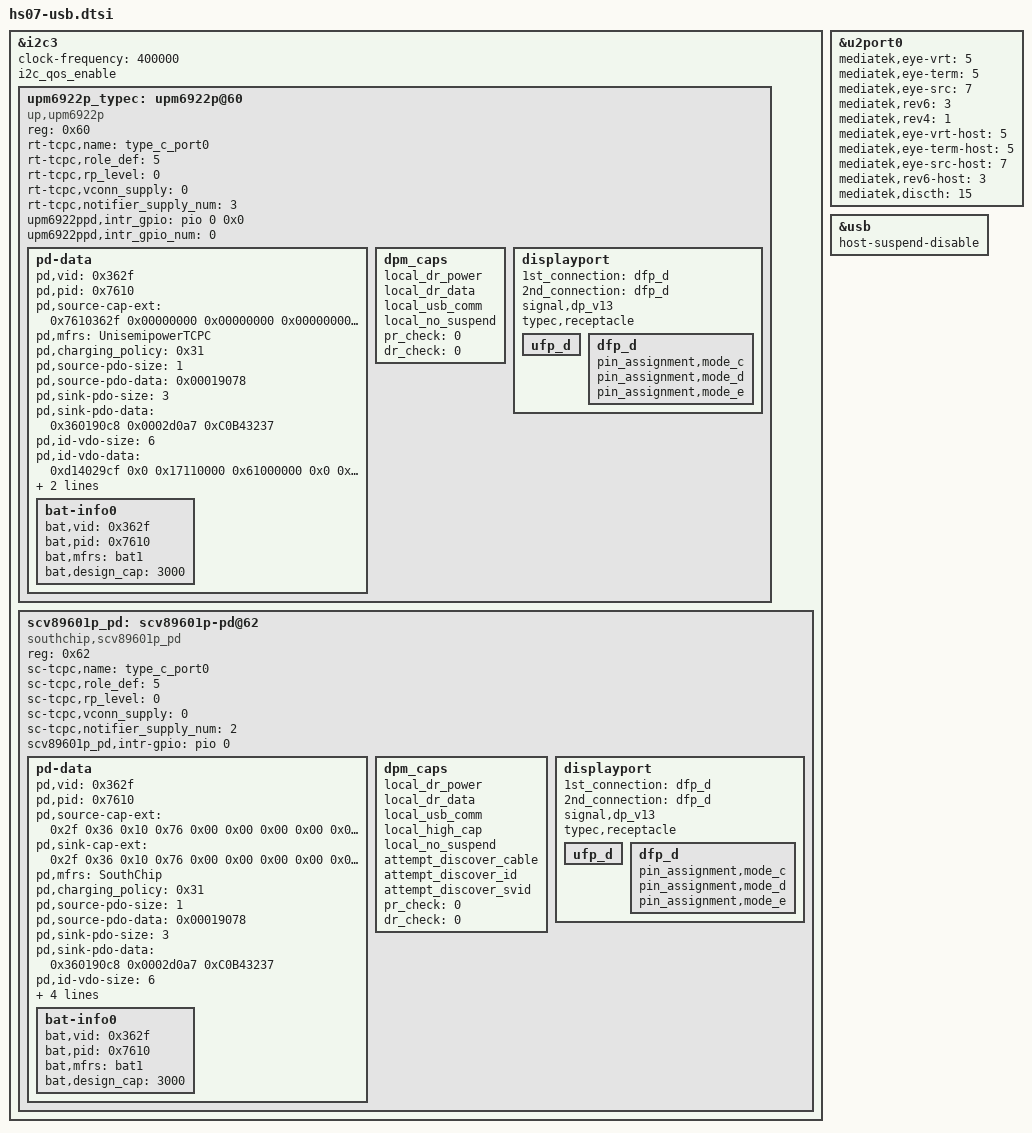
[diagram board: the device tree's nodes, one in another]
/* Note for tcpc data
* tcpc-dual,supported_modes : 0: dfp/ufp, 1: dfp, 2: ufp
* *-tcpc,role_def : 0: Unknown, 1: SNK, 2: SRC 3: DRP, 4: Try.SRC, 5: Try.SNK
* *-tcpc,rp_level: 0: Default, 1: 1.5, 2: 3.0
* *-tcpc,vconn_supply : 0: Never, 1: Always, 2: EMarkOnly, 3: StartOnly
* *-pd,charging_policy: VSAFE5V = 0, MAX_POWER = 1, CUSTOM = 2,MAX_POWER_LV = 0x21,
*                       MAX_POWER_LVIC = 0x31, MAX_POWER_HV = 0x41, MAX_POWER_HVIC = 0x51
* pd,sink-pdo-data: Fixed 5V, 500 mA <0x00019032>, Fixed 5V, 1A <0x00019064>, Fixed 5V, 2A <0x000190c8>
*                   Fixed 5V, 3A <0x0001912c>, Fixed 9V, 500 mA <0x0002d032>, Fixed 9V, 1A <0x0002d064>
*                   Fixed 9V, 2A <0x0002d0c8>, Fixed 9V, 3A <0x0002d12c>, Variable 5-9V, 1A <0x8642d064>
*                   Variable 5-9V, 2A <0x8642d0c8>, Variable 5-9V, 3A <0x8642d12c>, PPS 3V~5.9V, 3A <0xC0761E3C>
* No DP, host + device: pd,id-vdo-size = <6>;
*                       pd,id-vdo-data = <0xd14029cf 0x0 0x17110000
*                                         0x41800000 0x0 0x21800000>;
* With DP: pd,id-vdo-size = <6>;
*          pd,id-vdo-data = <0xd54029cf 0x0 0x17110000
*                            0x41800000 0x0 0x21800000>;
*/

/*HS07 code for HS07-18 by lina at 20250224 start*/
&i2c3 {
/*HS07 code for HS07-18 by lina at 20250224 end*/
	clock-frequency = <400000>;
	i2c_qos_enable;
	upm6922p_typec: upm6922p@60 {
		compatible = "up,upm6922p";
		reg = <0x60>;
		status = "okay";
		rt-tcpc,name = "type_c_port0"; /* tcpc_device's name */
		rt-tcpc,role_def = <5>; /* 0: Unknown, 1: SNK, 2: SRC */
					/* 3: DRP, 4: Try.SRC, 5: Try.SNK */
		rt-tcpc,rp_level = <0>; /* 0: Default, 1: 1.5, 2: 3.0 */
		/*HS07 code for HS07-752 by xiongxiaoliang at 20250415 start*/
		rt-tcpc,vconn_supply = <0>;  /* 0: Never, 1: Always, */
					     /* 2: EMarkOnly, 3: StartOnly */
		/*HS07 code for HS07-752 by xiongxiaoliang at 20250415 end*/
		rt-tcpc,notifier_supply_num = <3>;
		upm6922ppd,intr_gpio = <&pio 0 0x0>;
		upm6922ppd,intr_gpio_num = <0>;
		pd-data {
			pd,vid = <0x362f>;
			pd,pid = <0x7610>;
			pd,source-cap-ext = <0x7610362f 0x00000000 0x00000000
					     0x00000000 0x00000000 0x02000000>;
			pd,mfrs = "UnisemipowerTCPC";
			/*
			 *	VSAFE5V = 0, MAX_POWER = 1, CUSTOM = 2,
			 *	MAX_POWER_LV = 0x21, MAX_POWER_LVIC = 0x31
			 *	MAX_POWER_HV = 0x41, MAX_POWER_HVIC = 0x51
			 */
			 /*HS07 code for HS07-18 by lina at 20250224 start*/
			pd,charging_policy = <0x31>;
			/*HS07 code for HS07-18 by lina at 20250224 end*/
			/*
			 * Fixed 5V, 500 mA <0x00019032>
			 * Fixed 5V, 1A <0x00019064>
			 * Fixed 5V, 2A <0x000190c8>
			 * Fixed 5V, 3A <0x0001912c>
			 * Fixed 9V, 500 mA <0x0002d032>
			 * Fixed 9V, 1A <0x0002d064>
			 * Fixed 9V, 2A <0x0002d0c8>
			 * Fixed 9V, 3A <0x0002d12c>
			 * Variable 5-9V, 1A <0x8642d064>
			 * Variable 5-9V, 2A <0x8642d0c8>
			 * Variable 5-9V, 3A <0x8642d12c>
			 */
			pd,source-pdo-size = <1>;
			/*HS07 code for HS07-752 by xiongxiaoliang at 20250415 start*/
			pd,source-pdo-data = <0x00019078>;
			/*HS07 code for HS07-752 by xiongxiaoliang at 20250415 end*/
			pd,sink-pdo-size = <3>;
			/*HS07 code for HS07-2435 by xiongxiaoliang at 20250429 start*/
			pd,sink-pdo-data = <0x360190c8 0x0002d0a7 0xC0B43237>;
			/*HS07 code for HS07-2435 by xiongxiaoliang at 20250429 end*/
			/*
			 * No DP, host + device
			 *	pd,id-vdo-size = <6>;
			 *	pd,id-vdo-data = <0xd14029cf 0x0 0x17110000
						  0x61000000 0x0 0x41000000>;
			 * With DP Sink capability
			 *	pd,id-vdo-size = <6>;
			 *	pd,id-vdo-data = <0xd54029cf 0x0 0x17110000
						  0x61000000 0x0 0x41000000>;
			 */
			pd,id-vdo-size = <6>;
			pd,id-vdo-data = <0xd14029cf 0x0 0x17110000
					  0x61000000 0x0 0x41000000>;
			bat,nr = <1>;
			pd,country-nr = <0>;
			bat-info0 {
				bat,vid = <0x362f>;
				bat,pid = <0x7610>;
				bat,mfrs = "bat1";
				bat,design_cap = <3000>;
			};
		};
		/*HS07 code for HS07-18 by lina at 20250224 start*/
		dpm_caps {
		/*HS07 code for HS07-18 by lina at 20250224 end*/
			local_dr_power;
			local_dr_data;
			//local_ext_power;
			local_usb_comm;
			//local_usb_suspend;
			//local_high_cap;
			//local_give_back;
			local_no_suspend;
			/*HS07 code for HS07-752 by xiongxiaoliang at 20250415 start*/
			//local_vconn_supply;

			//attempt_discover_cable_dfp;
			//attempt_enter_dp_mode;
			//attempt_discover_cable;
			//attempt_discover_id;
			/*HS07 code for HS07-752 by xiongxiaoliang at 20250415 end*/
			/* 0: disable, 1: prefer-snk, 2: prefer-src */
			pr_check = <0>;
			//pr_reject_as_source;
			//pr_reject_as_sink;
			//pr_check_gp_source;
			//pr_check_gp_sink;

			/* 0: disable, 1: prefer_ufp, 2: prefer_dfp */
			dr_check = <0>;
			//dr_reject_as_dfp;
			//dr_reject_as_ufp;
		};
		displayport {
			/* connection type = "both", "ufp_d", "dfp_d" */
			1st_connection = "dfp_d";
			2nd_connection = "dfp_d";
			signal,dp_v13;
			//signal,dp_gen2;
			//usbr20_not_used;
			typec,receptacle;
			ufp_d {
				//pin_assignment,mode_a;
				//pin_assignment,mode_b;
				//pin_assignment,mode_c;
				//pin_assignment,mode_d;
				//pin_assignment,mode_e;
			};
			dfp_d {
				//pin_assignment,mode_a;
				//pin_assignment,mode_b;
				pin_assignment,mode_c;
				pin_assignment,mode_d;
				pin_assignment,mode_e;
				//pin_assignment,mode_f;
			};
		};
	};

	/* HS07 code for SR-AL7761A-01-164 by lina at 20250314 start */
	scv89601p_pd: scv89601p-pd@62{
		compatible = "southchip,scv89601p_pd";
		reg = <0x62>;
		status = "okay";
		sc-tcpc,name = "type_c_port0"; /* tcpc_device's name */
		sc-tcpc,role_def = <5>; /* 0: Unknown, 1: SNK, 2: SRC */
					/* 3: DRP, 4: Try.SRC, 5: Try.SNK */
		sc-tcpc,rp_level = <0>; /* 0: Default, 1: 1.5, 2: 3.0 */
		/*HS07 code for SR-AL7761A-01-20 by lina at 20250415 start*/
		sc-tcpc,vconn_supply  = <0>;  /* 0: Never, 1: Always, */
					      /* 2: EMarkOnly, 3: StartOnly */
		/*HS07 code for SR-AL7761A-01-20 by lina at 20250415 end*/
		sc-tcpc,notifier_supply_num = <2>;
		scv89601p_pd,intr-gpio = <&pio 0 IRQ_TYPE_EDGE_FALLING>;
		pd-data {
			/* HS07 code for HS07-1480 by lina at 20250425 start */
			pd,vid = <0x362f>;
			pd,pid = <0x7610>;
			pd,source-cap-ext = /bits/ 8 <0x2f 0x36 0x10 0x76
						      0x00 0x00 0x00 0x00
						      0x00 0x00 0x00 0x00
						      0x00 0x00 0x00 0x00
						      0x00 0x00 0x00 0x00
						      0x00 0x00 0x01 0x06
						      0x00>;
			pd,sink-cap-ext = /bits/ 8 <0x2f 0x36 0x10 0x76
							   0x00 0x00 0x00 0x00
							   0x01 0x00 0x00 0x00
							   0x00 0x00 0x00 0x00
							   0x01 0x00 0x00 0x00
							   0x00 0x00 0x00 0x00>;
			pd,mfrs = "SouthChip";
			/* HS07 code for HS07-1480 by lina at 20250425 end */

			/*
			 *	VSAFE5V = 0, MAX_POWER = 1, CUSTOM = 2,
			 *	MAX_POWER_LV = 0x21, MAX_POWER_LVIC = 0x31
			 *	MAX_POWER_HV = 0x41, MAX_POWER_HVIC = 0x51
			 */
			/*HS07 code for SR-AL7761A-01-20 by xiongxiaoliang at 20250319 start*/
			/*HS07 code for HS07-940 by lina at 20250418 start*/
			pd,charging_policy= <0x31>;
			/*HS07 code for HS07-940 by lina at 20250418 end*/

			/*
			 * Fixed 5V, 500 mA <0x00019032>
			 * Fixed 5V, 1A <0x00019064>
			 * Fixed 5V, 2A <0x000190c8>
			 * Fixed 5V, 3A <0x0001912c>
			 * Fixed 9V, 500 mA <0x0002d032>
			 * Fixed 9V, 1A <0x0002d064>
			 * Fixed 9V, 2A <0x0002d0c8>
			 * Fixed 9V, 3A <0x0002d12c>
			 * Variable 5-9V, 1A <0x8642d064>
			 * Variable 5-9V, 2A <0x8642d0c8>
			 * Variable 5-9V, 3A <0x8642d12c>
			 * PPS 3V~5.9V, 3A <0xC0761E3C>
			 */
			pd,source-pdo-size = <1>;
			/* Fixed 5V,0.5A */
			/*HS07 code for HS07-752 by xiongxiaoliang at 20250415 start*/
			pd,source-pdo-data = <0x00019078>;
			/*HS07 code for HS07-752 by xiongxiaoliang at 20250415 end*/
			/*HS07 code for SR-AL7761A-01-20 by lina at 20250415 start*/
			pd,sink-pdo-size = <3>;
			/*HS07 code for HS07-2435 by xiongxiaoliang at 20250429 start*/
			pd,sink-pdo-data = <0x360190c8 0x0002d0a7 0xC0B43237>;
			/*HS07 code for HS07-2435 by xiongxiaoliang at 20250429 end*/
			/*HS07 code for SR-AL7761A-01-20 by lina at 20250415 end*/
			/*HS07 code for SR-AL7761A-01-20 by xiongxiaoliang at 20250319 end*/
			/*0110 1110 0011 0010
			 * No DP, host + device
			 *	pd,id-vdo-size = <6>;
			 *	pd,id-vdo-data = <0xd14029cf 0x0 0x17110000
						  0x61000000 0x0 0x41000000>;
			 * With DP
			 *	pd,id-vdo-size = <6>;
			 *	pd,id-vdo-data = <0xd54029cf 0x0 0x17110000
						  0x61000000 0x0 0x41000000>;
			 */

			pd,id-vdo-size = <6>;
			/* HS07 code for HS07-1480 by lina at 20250425 start */
			/*HS07 code for SR-AL7761A-01-20 by lina at 20250415 start*/
			pd,id-vdo-data = <0xd140362f 0x0 0x76100000
						  0x61000000 0x0 0x41000000>;
			/*HS07 code for SR-AL7761A-01-20 by lina at 20250415 end*/

			bat,nr = <1>;
			pd,country_nr = <0>;

			bat-info0 {
				bat,vid = <0x362f>;
				bat,pid = <0x7610>;
				bat,mfrs = "bat1";
				bat,design_cap = <3000>;
			};
			/* HS07 code for HS07-1480 by lina at 20250425 end */

		};
		dpm_caps {
			local_dr_power;
			local_dr_data;
			//local_ext_power;
			local_usb_comm;
			//local_usb_suspend;
			/*HS07 code for SR-AL7761A-01-20 by lina at 20250415 start*/
			local_high_cap;
			/*HS07 code for SR-AL7761A-01-20 by lina at 20250415 end*/
			//local_give_back;
			local_no_suspend;
			/*HS07 code for HS07-752 by xiongxiaoliang at 20250514 start*/
			//local_vconn_supply;
			/*HS07 code for HS07-752 by xiongxiaoliang at 20250514 end*/

			//attempt_discover_cable_dfp;
			//attempt_enter_dp_mode;
			attempt_discover_cable;
			attempt_discover_id;
			attempt_discover_svid;

			/* 0: disable, 1: prefer_snk, 2: prefer_src */
			pr_check = <0>;
			//pr_reject_as_source;
			//pr_reject_as_sink;
			//pr_check_gp_source;
			//pr_check_gp_sink;

			/* 0: disable, 1: prefer_ufp, 2: prefer_dfp */
			dr_check = <0>;
			//dr_reject_as_dfp;
			//dr_reject_as_ufp;
		};
		displayport {
			/* connection type = "both", "ufp_d", "dfp_d" */
			1st_connection = "dfp_d";
			2nd_connection = "dfp_d";
			signal,dp_v13;
			//signal,dp_gen2;
			//usbr20_not_used;
			typec,receptacle;
			ufp_d {
				//pin_assignment,mode_a;
				//pin_assignment,mode_b;
				//pin_assignment,mode_c;
				//pin_assignment,mode_d;
				//pin_assignment,mode_e;
			};
			dfp_d {
				//pin_assignment,mode_a;
				//pin_assignment,mode_b;
				pin_assignment,mode_c;
				pin_assignment,mode_d;
				pin_assignment,mode_e;
				//pin_assignment,mode_f;
			};
		};
	};
	/* HS07 code for SR-AL7761A-01-164 by lina at 20250314 end */
};

/*HS07 code for HS07-18 by lina at 20250224 start*/
&u2port0 {
    mediatek,eye-vrt = <5>;
    mediatek,eye-term = <5>;
    mediatek,eye-src = <7>;
    mediatek,rev6 = <3>;
    mediatek,rev4 = <1>;
    mediatek,eye-vrt-host = <5>;
    mediatek,eye-term-host = <5>;
    mediatek,eye-src-host = <7>;
    mediatek,rev6-host = <3>;
    mediatek,discth = <15>;
};
/*HS07 code for HS07-18 by lina at 20250224 end*/

/* HST11 code for AX7800A-768 by wenyaqi at 20250519 start */
&usb {
    host-suspend-disable;
};
/* HST11 code for AX7800A-768 by wenyaqi at 20250519 end */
